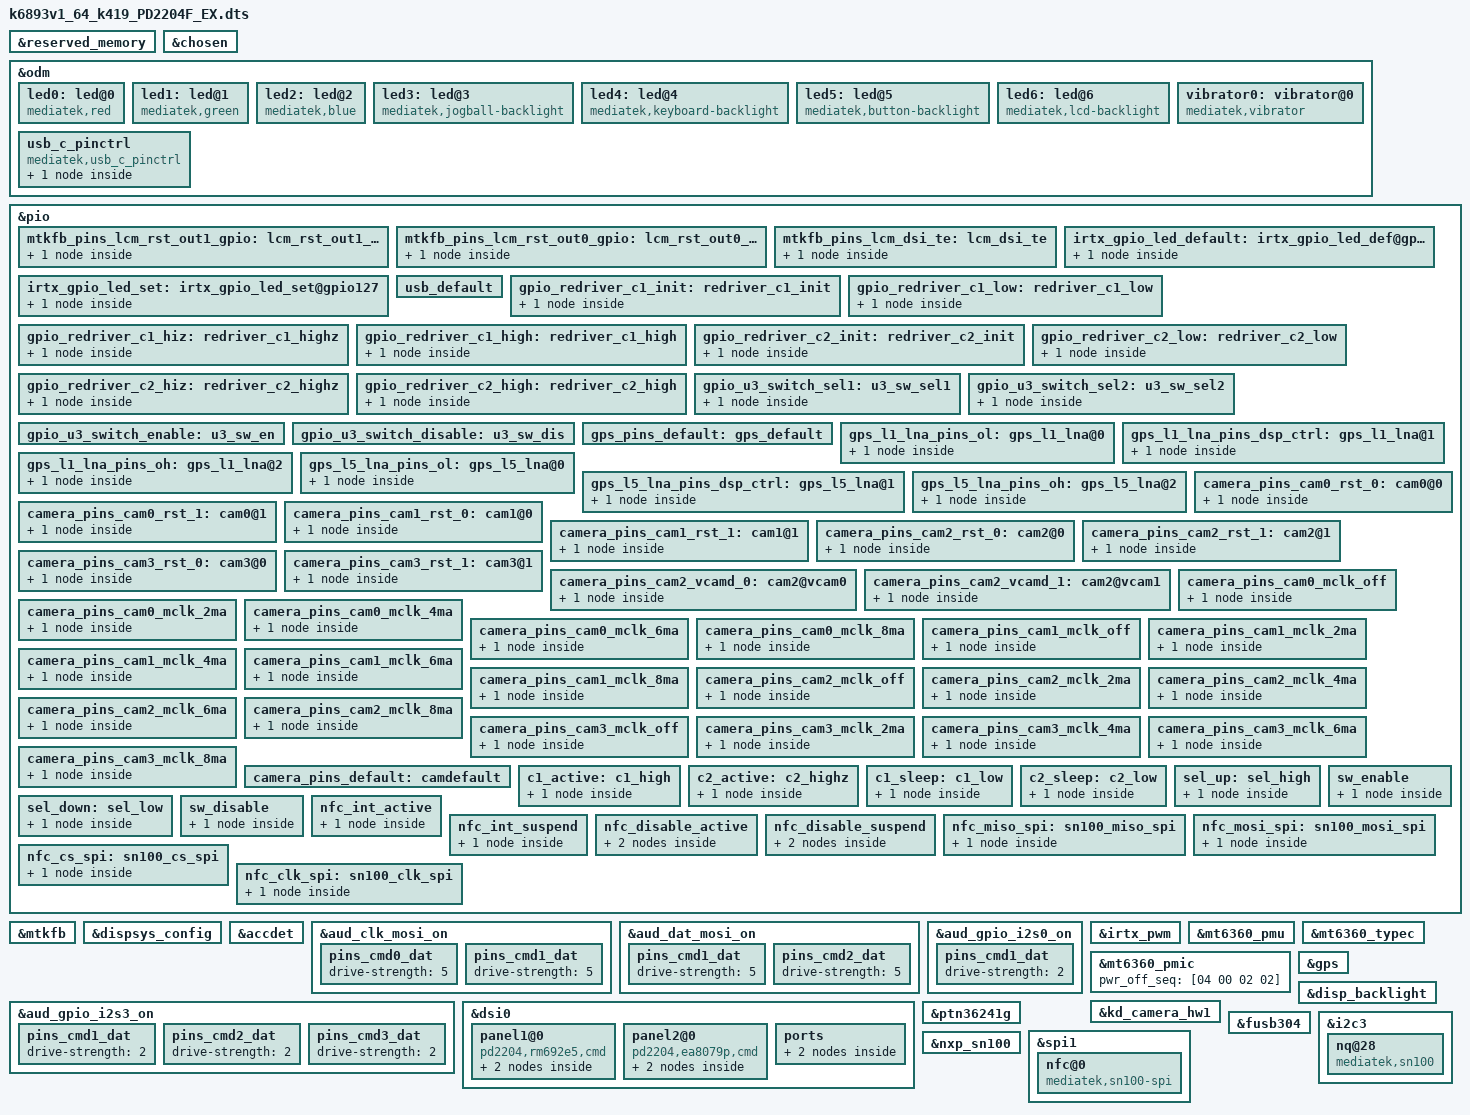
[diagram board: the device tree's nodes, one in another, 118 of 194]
// SPDX-License-Identifier: GPL-2.0
/*
 * Copyright (c) 2019 MediaTek Inc.
 *
 */
/dts-v1/;
/plugin/;
#include <dt-bindings/interrupt-controller/irq.h>
#include <dt-bindings/interrupt-controller/arm-gic.h>
#include <dt-bindings/spmi/spmi.h>
#include <dt-bindings/pinctrl/mt6885-pinfunc.h>
#include "mtk-vivo-tp-PD2204F_EX.dtsi"
#include "mediatek/fingerprint/mt6893-vivo-fp-PD2204F_EX.dtsi"
#include <generated/autoconf.h>

&reserved_memory {
};

/* chosen */
&chosen {

	atag,videolfb-fb_base_l = <0x7e020000>;
	atag,videolfb-fb_base_h = <0x0>;
	atag,videolfb-islcmfound = <1>;
	atag,videolfb-islcm_inited = <0>;
	atag,videolfb-fps= <6000>;
	atag,videolfb-vramSize= <0x1be0000>;
	atag,vivo-dsi-panel-type = "oled";
	atag,videolfb-project-name= "PD2204F_EX";
	atag,videolfb-lcmname=
		"nt35595_fhd_dsi_cmd_truly_nt50358_drv";
	default-backlight-level = <1146>;
};

&odm {
	led0:led@0 {
		compatible = "mediatek,red";
		led_mode = <0>;
		data = <1>;
		pwm_config = <0 0 0 0 0>;
	};
	led1:led@1 {
		compatible = "mediatek,green";
		led_mode = <0>;
		data = <1>;
		pwm_config = <0 0 0 0 0>;
	};
	led2:led@2 {
		compatible = "mediatek,blue";
		led_mode = <0>;
		data = <1>;
		pwm_config = <0 0 0 0 0>;
	};
	led3:led@3 {
		compatible = "mediatek,jogball-backlight";
		led_mode = <0>;
		data = <1>;
		pwm_config = <0 0 0 0 0>;
	};
	led4:led@4 {
		compatible = "mediatek,keyboard-backlight";
		led_mode = <0>;
		data = <1>;
		pwm_config = <0 0 0 0 0>;
	};
	led5:led@5 {
		compatible = "mediatek,button-backlight";
		led_mode = <0>;
		data = <1>;
		pwm_config = <0 0 0 0 0>;
	};
	led6:led@6 {
		compatible = "mediatek,lcd-backlight";
		led_mode = <4>;
		data = <1>;
		pwm_config = <0 1 0 0 0>;
	};
	vibrator0:vibrator@0 {
		compatible = "mediatek,vibrator";
		vib_timer = <25>;
		vib_limit = <9>;
		vib_vol= <9>;
	};
	usb_c_pinctrl:usb_c_pinctrl {
		compatible = "mediatek,usb_c_pinctrl";
	};
};

/* DISPSYS GPIO standardization */
&pio {

	mtkfb_pins_lcm_rst_out1_gpio: lcm_rst_out1_gpio {
		pins_cmd_dat {
			pinmux = <PINMUX_GPIO42__FUNC_GPIO42>;
			slew-rate = <1>;
			output-high;
		};
	};

	mtkfb_pins_lcm_rst_out0_gpio: lcm_rst_out0_gpio {
		pins_cmd_dat {
			pinmux = <PINMUX_GPIO42__FUNC_GPIO42>;
			slew-rate = <1>;
			output-low;
		};
	};

	mtkfb_pins_lcm_dsi_te: lcm_dsi_te {
		pins_cmd_dat {
			pinmux = <PINMUX_GPIO41__FUNC_DSI_TE>;
		};
	};
};

&mtkfb {
	pinctrl-names = "lcm_rst_out1_gpio", "lcm_rst_out0_gpio",
		"mode_te_te";
	pinctrl-4 = <&mtkfb_pins_lcm_rst_out1_gpio>;
	pinctrl-5 = <&mtkfb_pins_lcm_rst_out0_gpio>;
	pinctrl-6 = <&mtkfb_pins_lcm_dsi_te>;
	status = "okay";
};

&dispsys_config {
	pinctrl-names =
		"lcm_rst_out1_gpio", "lcm_rst_out0_gpio",
		"mode_te_te";
	pinctrl-0 = <&mtkfb_pins_lcm_rst_out1_gpio>;
	pinctrl-1 = <&mtkfb_pins_lcm_rst_out0_gpio>;
	pinctrl-2 = <&mtkfb_pins_lcm_dsi_te>;
	status = "okay";
};
/* DISPSYS GPIO standardization end */

/* accdet start */
&accdet {
	/* accdet micbias voltage: 0x09:2.85v 0x08:2.8v 0x07,
	 * 2.7v;0x05,2.5v;0x02,1.9v
	 */
	accdet-mic-vol = <7>;
	/* accdet pwm_width, pwm_thresh, fall_delay, rise_delay
	 * debounce0, debounce1, debounce3, debounce4
	 * eint pwm_width, eint pwm_thresh
	 * eint deb(debounce0, debounce1, debounce2, debounce3), inv_debounce
	 */
	headset-mode-setting = <0x500 0x500 1 0x1f0
				0x800 0x800 0x20 0x44
				0x4 0x1
				0x5 0x3 0x3 0x5 0xe>;
	accdet-plugout-debounce = <16>;
	/*1:ACC mode, 2:low cost without in bias, 6:low cost with in bias*/
	accdet-mic-mode = <2>;
	/*0--MD_MAX--UP_MAX--DW_MAX*/
	headset-three-key-threshold = <0 90 210 430>;
	headset-three-key-threshold-CDD = <0 121 192 600>;
	/*0--MD_MAX--VOICE_MAX--UP_MAX--DW_MAX*/
	headset-four-key-threshold = <0 60 106 210 430>;

	/* select VTH to 2v and 500k, use internal resitance */
	eint_use_ext_res = <0>;
	status = "okay";
};
/* accdet end */

/* Audio add for modify mosi & i2s driving */
/* 0:2mA 1:4mA 2:6mA 3:8mA 4:10mA 5:12mA 6:14mA 7:16mA */
&aud_clk_mosi_on {
	pins_cmd0_dat {
		drive-strength = <5>;
	};
	pins_cmd1_dat {
		drive-strength = <5>;
	};
};
&aud_dat_mosi_on {
	pins_cmd1_dat {
		drive-strength = <5>;
	};
	pins_cmd2_dat {
		drive-strength = <5>;
	};
};

&aud_gpio_i2s0_on {
	pins_cmd1_dat {
		drive-strength = <2>;
	};
};
&aud_gpio_i2s3_on {
	pins_cmd1_dat {
		drive-strength = <2>;
	};
	pins_cmd2_dat {
		drive-strength = <2>;
	};
	pins_cmd3_dat {
		drive-strength = <2>;
	};
};
/* Audio add End */

/* IRTX GPIO Start */
&irtx_pwm {
	pinctrl-names = "irtx_gpio_led_default", "irtx_gpio_led_set";
	pinctrl-0 = <&irtx_gpio_led_default>;
	pinctrl-1 = <&irtx_gpio_led_set>;
	status = "okay";
};
&pio {
	/* IRTX GPIO Settings -Start */
	/* default: GPIO0, output, high */
	irtx_gpio_led_default:irtx_gpio_led_def@gpio127 {
		pins_cmd_dat {
			pinmux = <PINMUX_GPIO127__FUNC_GPIO127>;
			slew-rate = <1>;
			bias-disable;
			output-low;
			input-schmitt-enable = <0>;
		};
	};

	irtx_gpio_led_set:irtx_gpio_led_set@gpio127 {
		pins_cmd_dat {
			pinmux = <PINMUX_GPIO127__FUNC_PWM_3>;
			slew-rate = <1>;
			output-high;
		};
	};
}; /* IRTX GPIO Settings -End */


&mt6360_pmu {
	mt6360,intr_gpio_num = <24>; // direct defined GPIO num //
	mt6360,intr_gpio = <&pio 24 0x0>;
};

&mt6360_pmic  {
	pwr_off_seq = [04 00 02 02];
};

&mt6360_typec {
	mt6360pd,intr_gpio_num = <25>; /* direct defined GPIO num */
	mt6360pd,intr_gpio = <&pio 25 0x0>;
};

/* USB SWITCH GPIO start */
&pio {
	usb_default: usb_default {
	};

	gpio_redriver_c1_init: redriver_c1_init {
		pins_cmd_dat {
			pinmux = <PINMUX_GPIO113__FUNC_GPIO113>;
			slew-rate = <1>;
			output-low;
		};
	};

	gpio_redriver_c1_low: redriver_c1_low {
		pins_cmd_dat {
			pinmux = <PINMUX_GPIO113__FUNC_GPIO113>;
			slew-rate = <1>;
			output-low;
		};
	};

	gpio_redriver_c1_hiz: redriver_c1_highz {
		pins_cmd_dat {
			pinmux = <PINMUX_GPIO113__FUNC_GPIO113>;
			slew-rate= <0>;
			bias-disable;
		};
	};

	gpio_redriver_c1_high: redriver_c1_high {
		pins_cmd_dat {
			pinmux = <PINMUX_GPIO113__FUNC_GPIO113>;
			slew-rate = <1>;
			output-high;
		};
	};

	gpio_redriver_c2_init: redriver_c2_init {
		pins_cmd_dat {
			pinmux = <PINMUX_GPIO112__FUNC_GPIO112>;
			slew-rate = <1>;
			output-low;
		};
	};

	gpio_redriver_c2_low: redriver_c2_low {
		pins_cmd_dat {
			pinmux = <PINMUX_GPIO112__FUNC_GPIO112>;
			slew-rate = <1>;
			output-low;
		};
	};

	gpio_redriver_c2_hiz: redriver_c2_highz {
		pins_cmd_dat {
			pinmux = <PINMUX_GPIO112__FUNC_GPIO112>;
			slew-rate= <0>;
			bias-disable;
		};
	};

	gpio_redriver_c2_high: redriver_c2_high {
		pins_cmd_dat {
			pinmux = <PINMUX_GPIO112__FUNC_GPIO112>;
			slew-rate = <1>;
			output-high;
		};
	};

	gpio_u3_switch_sel1: u3_sw_sel1 {
		pins_cmd_dat {
			pinmux = <PINMUX_GPIO111__FUNC_GPIO111>;
			slew-rate = <1>;
			output-low;
		};
	};

	gpio_u3_switch_sel2: u3_sw_sel2 {
		pins_cmd_dat {
			pinmux = <PINMUX_GPIO111__FUNC_GPIO111>;
			slew-rate = <1>;
			output-high;
		};
	};

	gpio_u3_switch_enable: u3_sw_en {
	};

	gpio_u3_switch_disable: u3_sw_dis {
	};
};

&usb_c_pinctrl {
	pinctrl-names = "usb_default",
		"redrv_c1_init",
		"redrv_c1_low",
		"redrv_c1_hiz",
		"redrv_c1_high",
		"redrv_c2_init",
		"redrv_c2_low",
		"redrv_c2_hiz",
		"redrv_c2_high",
		"switch_sel1",
		"switch_sel2",
		"switch_enable",
		"switch_disable";

	pinctrl-0 = <&usb_default>;
	pinctrl-1 = <&gpio_redriver_c1_init>;
	pinctrl-2 = <&gpio_redriver_c1_low>;
	pinctrl-3 = <&gpio_redriver_c1_hiz>;
	pinctrl-4 = <&gpio_redriver_c1_high>;
	pinctrl-5 = <&gpio_redriver_c2_init>;
	pinctrl-6 = <&gpio_redriver_c2_low>;
	pinctrl-7 = <&gpio_redriver_c2_hiz>;
	pinctrl-8 = <&gpio_redriver_c2_high>;
	pinctrl-9 = <&gpio_u3_switch_sel1>;
	pinctrl-10 = <&gpio_u3_switch_sel2>;
	pinctrl-11 = <&gpio_u3_switch_enable>;
	pinctrl-12 = <&gpio_u3_switch_disable>;
	status = "okay";

	usb_switch-data {
		en_pin_num = <0>;
		en_pin_val = <0>;
		sel_pin_num = <111>;
		sel_pin_val = <1>;
		c1_pin_num = <113>;
		c1_pin_val = <2>;
		c2_pin_num = <112>;
		c2_pin_val = <1>;
	};
};
/* USB SWITCH GPIO end */

/* GPS GPIO standardization start */
&pio {
	gps_pins_default: gps_default {
	};

	gps_l1_lna_pins_ol: gps_l1_lna@0 {
		pins_cmd_dat {
			pinmux = <PINMUX_GPIO162__FUNC_GPIO162>;
			output-low;
		};
	};
	gps_l1_lna_pins_dsp_ctrl: gps_l1_lna@1 {
		pins_cmd_dat {
			pinmux = <PINMUX_GPIO162__FUNC_GPS_L1_ELNA_EN>;
		};
	};
	gps_l1_lna_pins_oh: gps_l1_lna@2 {
		pins_cmd_dat {
			pinmux = <PINMUX_GPIO162__FUNC_GPIO162>;
			output-high;
		};
	};

	gps_l5_lna_pins_ol: gps_l5_lna@0 {
		pins_cmd_dat {
			pinmux = <PINMUX_GPIO163__FUNC_GPIO163>;
			output-low;
		};
	};
	gps_l5_lna_pins_dsp_ctrl: gps_l5_lna@1 {
		pins_cmd_dat {
			pinmux = <PINMUX_GPIO163__FUNC_GPS_L5_ELNA_EN>;
		};
	};
	gps_l5_lna_pins_oh: gps_l5_lna@2 {
		pins_cmd_dat {
			pinmux = <PINMUX_GPIO163__FUNC_GPIO163>;
			output-high;
		};
	};
};

&gps {
	pinctrl-names = "default",
		"gps_l1_lna_disable",
		"gps_l1_lna_dsp_ctrl",
		"gps_l1_lna_enable",
		"gps_l5_lna_disable",
		"gps_l5_lna_dsp_ctrl",
		"gps_l5_lna_enable";
	pinctrl-0 = <&gps_pins_default>;
	pinctrl-1 = <&gps_l1_lna_pins_ol>;
	pinctrl-2 = <&gps_l1_lna_pins_dsp_ctrl>;
	pinctrl-3 = <&gps_l1_lna_pins_oh>;
	pinctrl-4 = <&gps_l5_lna_pins_ol>;
	pinctrl-5 = <&gps_l5_lna_pins_dsp_ctrl>;
	pinctrl-6 = <&gps_l5_lna_pins_oh>;
	status = "okay";
};
/* GPS GPIO standardization end */

&dispsys_config {
	pinctrl-names =
	"lcm_rst_out1_gpio", "lcm_rst_out0_gpio",
		"mode_te_te";
	pinctrl-0 = <&mtkfb_pins_lcm_rst_out1_gpio>;
	pinctrl-1 = <&mtkfb_pins_lcm_rst_out0_gpio>;
	pinctrl-2 = <&mtkfb_pins_lcm_dsi_te>;

	helper-name = "MTK_DRM_OPT_STAGE",
		"MTK_DRM_OPT_USE_CMDQ",
		"MTK_DRM_OPT_USE_M4U",
		"MTK_DRM_OPT_SODI_SUPPORT",
		"MTK_DRM_OPT_IDLE_MGR",
		"MTK_DRM_OPT_IDLEMGR_SWTCH_DECOUPLE",
		"MTK_DRM_OPT_IDLEMGR_BY_REPAINT",
		"MTK_DRM_OPT_IDLEMGR_ENTER_ULPS",
		"MTK_DRM_OPT_IDLEMGR_KEEP_LP11",
		"MTK_DRM_OPT_DYNAMIC_RDMA_GOLDEN_SETTING",
		"MTK_DRM_OPT_IDLEMGR_DISABLE_ROUTINE_IRQ",
		"MTK_DRM_OPT_MET_LOG",
		"MTK_DRM_OPT_USE_PQ",
		"MTK_DRM_OPT_ESD_CHECK_RECOVERY",
		"MTK_DRM_OPT_ESD_CHECK_SWITCH",
		"MTK_DRM_OPT_PRESENT_FENCE",
		"MTK_DRM_OPT_RDMA_UNDERFLOW_AEE",
		"MTK_DRM_OPT_DSI_UNDERRUN_AEE",
		"MTK_DRM_OPT_HRT",
		"MTK_DRM_OPT_HRT_MODE",
		"MTK_DRM_OPT_DELAYED_TRIGGER",
		"MTK_DRM_OPT_OVL_EXT_LAYER",
		"MTK_DRM_OPT_AOD",
		"MTK_DRM_OPT_RPO",
		"MTK_DRM_OPT_DUAL_PIPE",
		"MTK_DRM_OPT_DC_BY_HRT",
		"MTK_DRM_OPT_OVL_WCG",
		"MTK_DRM_OPT_OVL_SBCH",
		"MTK_DRM_OPT_COMMIT_NO_WAIT_VBLANK",
		"MTK_DRM_OPT_MET",
		"MTK_DRM_OPT_REG_PARSER_RAW_DUMP",
		"MTK_DRM_OPT_VP_PQ",
		"MTK_DRM_OPT_GAME_PQ",
		"MTK_DRM_OPT_MMPATH",
		"MTK_DRM_OPT_HBM",
		"MTK_DRM_OPT_VDS_PATH_SWITCH",
		"MTK_DRM_OPT_LAYER_REC",
		"MTK_DRM_OPT_CLEAR_LAYER",
		"MTK_DRM_OPT_LFR",
		"MTK_DRM_OPT_SF_PF",
		"MTK_DRM_OPT_DYN_MIPI_CHANGE",
		"MTK_DRM_OPT_PRIM_DUAL_PIPE";

	helper-value = <0>, /*MTK_DRM_OPT_STAGE*/
		<1>, /*MTK_DRM_OPT_USE_CMDQ*/
		<1>, /*MTK_DRM_OPT_USE_M4U*/
		<0>, /*MTK_DRM_OPT_SODI_SUPPORT*/
		<1>, /*MTK_DRM_OPT_IDLE_MGR*/
		<0>, /*MTK_DRM_OPT_IDLEMGR_SWTCH_DECOUPLE*/
		<1>, /*MTK_DRM_OPT_IDLEMGR_BY_REPAINT*/
		<0>, /*MTK_DRM_OPT_IDLEMGR_ENTER_ULPS*/
		<0>, /*MTK_DRM_OPT_IDLEMGR_KEEP_LP11*/
		<0>, /*MTK_DRM_OPT_DYNAMIC_RDMA_GOLDEN_SETTING*/
		<1>, /*MTK_DRM_OPT_IDLEMGR_DISABLE_ROUTINE_IRQ*/
		<0>, /*MTK_DRM_OPT_MET_LOG*/
		<1>, /*MTK_DRM_OPT_USE_PQ*/
		<1>, /*MTK_DRM_OPT_ESD_CHECK_RECOVERY*/
		<1>, /*MTK_DRM_OPT_ESD_CHECK_SWITCH*/
		<1>, /*MTK_DRM_OPT_PRESENT_FENCE*/
		<0>, /*MTK_DRM_OPT_RDMA_UNDERFLOW_AEE*/
		<1>, /*MTK_DRM_OPT_DSI_UNDERRUN_AEE*/
		<1>, /*MTK_DRM_OPT_HRT*/
		<1>, /*MTK_DRM_OPT_HRT_MODE*/
		<0>, /*MTK_DRM_OPT_DELAYED_TRIGGER*/
		<1>, /*MTK_DRM_OPT_OVL_EXT_LAYER*/
		<1>, /*MTK_DRM_OPT_AOD*/
		<1>, /*MTK_DRM_OPT_RPO*/
		<0>, /*MTK_DRM_OPT_DUAL_PIPE*/
		<0>, /*MTK_DRM_OPT_DC_BY_HRT*/
		<1>, /*MTK_DRM_OPT_OVL_WCG*/
		<0>, /*MTK_DRM_OPT_OVL_SBCH*/
		<1>, /*MTK_DRM_OPT_COMMIT_NO_WAIT_VBLANK*/
		<0>, /*MTK_DRM_OPT_MET*/
		<0>, /*MTK_DRM_OPT_REG_PARSER_RAW_DUMP*/
		<0>, /*MTK_DRM_OPT_VP_PQ*/
		<0>, /*MTK_DRM_OPT_GAME_PQ*/
		<0>, /*MTK_DRM_OPT_MMPATH*/
		<1>, /*MTK_DRM_OPT_HBM*/
		<0>, /*MTK_DRM_OPT_VDS_PATH_SWITCH*/
		<0>, /*MTK_DRM_OPT_LAYER_REC*/
		<1>, /*MTK_DRM_OPT_CLEAR_LAYER*/
		<1>, /*MTK_DRM_OPT_LFR*/
		<1>, /*MTK_DRM_OPT_SF_PF*/
		<1>, /*MTK_DRM_OPT_DYN_MIPI_CHANGE*/
		<1>; /*MTK_DRM_OPT_PRIM_DUAL_PIPE*/

};

&disp_backlight {
	max-brightness = <4095>;
	led-bits = <12>;
	default-brightness = <573>;
	trans-bits = <12>;
	default-state = "on";
};

&dsi0 {
	status = "okay";
	#address-cells = <1>;
	#size-cells = <0>;
	panel1@0 {
		compatible = "pd2204,rm692e5,cmd";
		reg = <0>;
		vddi-supply = <&mt_pmic_vm18_ldo_reg>;
		vci-supply = <&mt_pmic_vfp_ldo_reg>;
		reset-gpios = <&pio 42 0>;
		vddr-gpios = <&pio 191 0>;
		err_flag-gpios = <&pio 7 0>;
		elvdd_ctrl-gpios = <&pio 55 0>;
		board-gpios = <&pio 52 0>;
		vddr_mos_ctrl-gpios = <&pio 13 0>;
		pinctrl-names = "default";
		port {
			panel_in1: endpoint {
				remote-endpoint = <&dsi_out>;
			};
		};
	};
	panel2@0 {
		compatible = "pd2204,ea8079p,cmd";
		reg = <1>;
		vddi-supply = <&mt_pmic_vm18_ldo_reg>;
		vci-supply = <&mt_pmic_vfp_ldo_reg>;
		reset-gpios = <&pio 42 0>;
		vddr-gpios = <&pio 191 0>;
		err_flag-gpios = <&pio 7 0>;
		elvdd_ctrl-gpios = <&pio 55 0>;
		board-gpios = <&pio 52 0>;
		vddr_mos_ctrl-gpios = <&pio 13 0>;
		pinctrl-names = "default";
		port {
			panel_in2: endpoint {
				remote-endpoint = <&dsi_out>;
			};
		};
	};
	ports {
		port {
			dsi_out: endpoint {
				remote-endpoint = <&panel_in1>;
			};
		};
	};
};

/* CAMERA GPIO standardization */
&pio {
	camera_pins_cam0_rst_0: cam0@0 {
		pins_cmd_dat {
			pinmux = <PINMUX_GPIO132__FUNC_GPIO132>;
			slew-rate = <1>;
			output-low;
		};
	};
	camera_pins_cam0_rst_1: cam0@1 {
		pins_cmd_dat {
			pinmux = <PINMUX_GPIO132__FUNC_GPIO132>;
			slew-rate = <1>;
			output-high;
		};
	};
	camera_pins_cam1_rst_0: cam1@0 {
		pins_cmd_dat {
			pinmux = <PINMUX_GPIO131__FUNC_GPIO131>;
			slew-rate = <1>;
			output-low;
		};
	};
	camera_pins_cam1_rst_1: cam1@1 {
		pins_cmd_dat {
			pinmux = <PINMUX_GPIO131__FUNC_GPIO131>;
			slew-rate = <1>;
			output-high;
		};
	};
	camera_pins_cam2_rst_0: cam2@0 {
		pins_cmd_dat {
			pinmux = <PINMUX_GPIO11__FUNC_GPIO11>;
			slew-rate = <1>;
			output-low;
		};
	};
	camera_pins_cam2_rst_1: cam2@1 {
		pins_cmd_dat {
			pinmux = <PINMUX_GPIO11__FUNC_GPIO11>;
			slew-rate = <1>;
			output-high;
		};
	};
	camera_pins_cam3_rst_0: cam3@0 {
		pins_cmd_dat {
			pinmux = <PINMUX_GPIO10__FUNC_GPIO10>;
			slew-rate = <1>;
			output-low;
		};
	};
	camera_pins_cam3_rst_1: cam3@1 {
		pins_cmd_dat {
			pinmux = <PINMUX_GPIO10__FUNC_GPIO10>;
			slew-rate = <1>;
			output-high;
		};
	};
/*main OIS power start
	camera_main_af_pins_vddois_low: camera_main_af_vddois_low {
		pins_cmd_dat {
			pinmux = <PINMUX_GPIO135__FUNC_GPIO135>;
			slew-rate = <1>;
			output-low;
		};
	};
	camera_main_af_pins_vddois_high: camera_main_af_vddois_high {
		pins_cmd_dat {
			pinmux = <PINMUX_GPIO135__FUNC_GPIO135>;
			slew-rate = <1>;
			output-high;
		};
	};
main OIS power end*/
/*main2 power start*/
	camera_pins_cam2_vcamd_0: cam2@vcam0 {
		pins_cmd_dat {
			pinmux = <PINMUX_GPIO135__FUNC_GPIO135>;
			slew-rate = <1>;
			output-low;
		};
	};
	camera_pins_cam2_vcamd_1: cam2@vcam1 {
		pins_cmd_dat {
			pinmux = <PINMUX_GPIO135__FUNC_GPIO135>;
			slew-rate = <1>;
			output-high;
		};
	};
/*main2 power end*/
/*main power start*/
/*main power end*/
/*sub power start*/
/*sub power end*/
/*main2 power start*/
/*main2 power end*/
/*mclk power start*/
	camera_pins_cam0_mclk_off: camera_pins_cam0_mclk_off {
		pins_cmd_dat {
			pinmux = <PINMUX_GPIO149__FUNC_GPIO149>;
			drive-strength = <0>;
		};
	};
	camera_pins_cam0_mclk_2ma: camera_pins_cam0_mclk_2ma {
		pins_cmd_dat {
			pinmux = <PINMUX_GPIO149__FUNC_CMMCLK0>;
			drive-strength = <0>;
		};
	};
	camera_pins_cam0_mclk_4ma: camera_pins_cam0_mclk_4ma {
		pins_cmd_dat {
			pinmux = <PINMUX_GPIO149__FUNC_CMMCLK0>;
			drive-strength = <1>;
		};
	};
	camera_pins_cam0_mclk_6ma: camera_pins_cam0_mclk_6ma {
		pins_cmd_dat {
			pinmux = <PINMUX_GPIO149__FUNC_CMMCLK0>;
			drive-strength = <2>;
		};
	};
	camera_pins_cam0_mclk_8ma: camera_pins_cam0_mclk_8ma {
		pins_cmd_dat {
			pinmux = <PINMUX_GPIO149__FUNC_CMMCLK0>;
			drive-strength = <3>;
		};
	};
	camera_pins_cam1_mclk_off: camera_pins_cam1_mclk_off {
		pins_cmd_dat {
			pinmux = <PINMUX_GPIO137__FUNC_GPIO137>;
			drive-strength = <0>;
		};
	};
	camera_pins_cam1_mclk_2ma: camera_pins_cam1_mclk_2ma {
		pins_cmd_dat {
			pinmux = <PINMUX_GPIO137__FUNC_CMMCLK4>;
			drive-strength = <0>;
		};
	};
	camera_pins_cam1_mclk_4ma: camera_pins_cam1_mclk_4ma {
		pins_cmd_dat {
			pinmux = <PINMUX_GPIO137__FUNC_CMMCLK4>;
			drive-strength = <1>;
		};
	};
	camera_pins_cam1_mclk_6ma: camera_pins_cam1_mclk_6ma {
		pins_cmd_dat {
			pinmux = <PINMUX_GPIO137__FUNC_CMMCLK4>;
			drive-strength = <2>;
		};
	};
	camera_pins_cam1_mclk_8ma: camera_pins_cam1_mclk_8ma {
		pins_cmd_dat {
			pinmux = <PINMUX_GPIO137__FUNC_CMMCLK4>;
			drive-strength = <3>;
		};
	};
	camera_pins_cam2_mclk_off: camera_pins_cam2_mclk_off {
		pins_cmd_dat {
			pinmux = <PINMUX_GPIO151__FUNC_GPIO151>;
			drive-strength = <0>;
		};
	};
	camera_pins_cam2_mclk_2ma: camera_pins_cam2_mclk_2ma {
		pins_cmd_dat {
			pinmux = <PINMUX_GPIO151__FUNC_CMMCLK2>;
			drive-strength = <0>;
		};
	};
	camera_pins_cam2_mclk_4ma: camera_pins_cam2_mclk_4ma {
		pins_cmd_dat {
			pinmux = <PINMUX_GPIO151__FUNC_CMMCLK2>;
			drive-strength = <1>;
		};
	};
	camera_pins_cam2_mclk_6ma: camera_pins_cam2_mclk_6ma {
		pins_cmd_dat {
			pinmux = <PINMUX_GPIO151__FUNC_CMMCLK2>;
			drive-strength = <2>;
		};
	};
	camera_pins_cam2_mclk_8ma: camera_pins_cam2_mclk_8ma {
		pins_cmd_dat {
			pinmux = <PINMUX_GPIO151__FUNC_CMMCLK2>;
			drive-strength = <3>;
		};
	};
	camera_pins_cam3_mclk_off: camera_pins_cam3_mclk_off {
		pins_cmd_dat {
			pinmux = <PINMUX_GPIO150__FUNC_GPIO150>;
			drive-strength = <0>;
		};
	};
	camera_pins_cam3_mclk_2ma: camera_pins_cam3_mclk_2ma {
		pins_cmd_dat {
			pinmux = <PINMUX_GPIO150__FUNC_CMMCLK1>;
			drive-strength = <0>;
		};
	};
	camera_pins_cam3_mclk_4ma: camera_pins_cam3_mclk_4ma {
		pins_cmd_dat {
			pinmux = <PINMUX_GPIO150__FUNC_CMMCLK1>;
			drive-strength = <1>;
		};
	};
	camera_pins_cam3_mclk_6ma: camera_pins_cam3_mclk_6ma {
		pins_cmd_dat {
			pinmux = <PINMUX_GPIO150__FUNC_CMMCLK1>;
			drive-strength = <2>;
		};
	};
	camera_pins_cam3_mclk_8ma: camera_pins_cam3_mclk_8ma {
		pins_cmd_dat {
			pinmux = <PINMUX_GPIO150__FUNC_CMMCLK1>;
			drive-strength = <3>;
		};
	};
	camera_pins_default: camdefault {
	};
	/*mclk end*/
};
/* CAMERA specify sensor */
&kd_camera_hw1 {
	pinctrl-names = "default",
			"cam0_rst0", "cam0_rst1",
			"cam1_rst0", "cam1_rst1",
			"cam2_rst0", "cam2_rst1",
			"cam3_rst0", "cam3_rst1",
			//"cam0_ldo_vddois_0", "cam0_ldo_vddois_1",
			"cam2_ldo_vcamd_0", "cam2_ldo_vcamd_1",
			"cam0_mclk_off",
			"cam0_mclk_2mA", "cam0_mclk_4mA",
			"cam0_mclk_6mA", "cam0_mclk_8mA",
			"cam1_mclk_off",
			"cam1_mclk_2mA", "cam1_mclk_4mA",
			"cam1_mclk_6mA", "cam1_mclk_8mA",
			"cam2_mclk_off",
			"cam2_mclk_2mA", "cam2_mclk_4mA",
			"cam2_mclk_6mA", "cam2_mclk_8mA",
			"cam3_mclk_off",
			"cam3_mclk_2mA", "cam3_mclk_4mA",
			"cam3_mclk_6mA", "cam3_mclk_8mA";

	pinctrl-0 = <&camera_pins_default>;
	pinctrl-1 = <&camera_pins_cam0_rst_0>;
	pinctrl-2 = <&camera_pins_cam0_rst_1>;
	pinctrl-3 = <&camera_pins_cam1_rst_0>;
	pinctrl-4 = <&camera_pins_cam1_rst_1>;
	pinctrl-5 = <&camera_pins_cam2_rst_0>;
	pinctrl-6 = <&camera_pins_cam2_rst_1>;
	pinctrl-7 = <&camera_pins_cam3_rst_0>;
	pinctrl-8 = <&camera_pins_cam3_rst_1>;
	pinctrl-9 = <&camera_pins_cam2_vcamd_0>;
	pinctrl-10 = <&camera_pins_cam2_vcamd_1>;
	pinctrl-11 = <&camera_pins_cam0_mclk_off>;
	pinctrl-12 = <&camera_pins_cam0_mclk_2ma>;
	pinctrl-13 = <&camera_pins_cam0_mclk_4ma>;
	pinctrl-14 = <&camera_pins_cam0_mclk_6ma>;
	pinctrl-15 = <&camera_pins_cam0_mclk_8ma>;
	pinctrl-16 = <&camera_pins_cam1_mclk_off>;
	pinctrl-17 = <&camera_pins_cam1_mclk_2ma>;
	pinctrl-18 = <&camera_pins_cam1_mclk_4ma>;
	pinctrl-19 = <&camera_pins_cam1_mclk_6ma>;
	pinctrl-20 = <&camera_pins_cam1_mclk_8ma>;
	pinctrl-21 = <&camera_pins_cam2_mclk_off>;
	pinctrl-22 = <&camera_pins_cam2_mclk_2ma>;
	pinctrl-23 = <&camera_pins_cam2_mclk_4ma>;
	pinctrl-24 = <&camera_pins_cam2_mclk_6ma>;
	pinctrl-25 = <&camera_pins_cam2_mclk_8ma>;
	pinctrl-26 = <&camera_pins_cam3_mclk_off>;
	pinctrl-27 = <&camera_pins_cam3_mclk_2ma>;
	pinctrl-28 = <&camera_pins_cam3_mclk_4ma>;
	pinctrl-29 = <&camera_pins_cam3_mclk_6ma>;
	pinctrl-30 = <&camera_pins_cam3_mclk_8ma>;
	status = "okay";
};
/* CAMERA specify sensor end */


/* usb typec mux */
&pio {
	c1_active: c1_high {
		pins_cmd_dat {
			pinmux = <PINMUX_GPIO113__FUNC_GPIO113>;
			output-high;
		};
	};

	c2_active: c2_highz {
		pins_cmd_dat {
			pinmux = <PINMUX_GPIO112__FUNC_GPIO112>;
			input-enable;
			bias-disable;
		};
	};

	c1_sleep: c1_low {
		pins_cmd_dat {
			pinmux = <PINMUX_GPIO113__FUNC_GPIO113>;
			output-low;
		};
	};

	c2_sleep: c2_low {
		pins_cmd_dat {
			pinmux = <PINMUX_GPIO112__FUNC_GPIO112>;
			output-low;
		};
	};

	sel_up: sel_high {
		pins_cmd_dat {
			pinmux = <PINMUX_GPIO111__FUNC_GPIO111>;
			output-high;
		};
	};

	sel_down: sel_low {
		pins_cmd_dat {
			pinmux = <PINMUX_GPIO111__FUNC_GPIO111>;
			output-low;
		};
	};

	sw_enable: sw_enable {
		pins_cmd_dat {
			pinmux = <PINMUX_GPIO110__FUNC_GPIO110>;
			output-low;
		};
	};

	sw_disable: sw_disable {
		pins_cmd_dat {
			pinmux = <PINMUX_GPIO110__FUNC_GPIO110>;
			output-low;
		};
	};
};

&ptn36241g {
	pinctrl-names = "c1_active", "c1_sleep",
		"c2_active", "c2_sleep";
	pinctrl-0 = <&c1_active>;
	pinctrl-1 = <&c1_sleep>;
	pinctrl-2 = <&c2_active>;
	pinctrl-3 = <&c2_sleep>;
	status = "okay";
};

&fusb304 {
	pinctrl-names = "sel_up", "sel_down",
		"enable", "disable";
	pinctrl-0 = <&sel_up>;
	pinctrl-1 = <&sel_down>;
	pinctrl-2 = <&sw_enable>;
	pinctrl-3 = <&sw_disable>;
	status = "okay";
};

/*nfc liuyang4 begin*/
/*NFC*/
&pio {
	nfc_int_active: nfc_int_active {
		pins_cmd0_dat {
			pinmux = <PINMUX_GPIO16__FUNC_GPIO16>;
			bias-pull-up;
		};
	};
	nfc_int_suspend: nfc_int_suspend {
		pins_cmd0_dat {
			pinmux = <PINMUX_GPIO16__FUNC_GPIO16>;
			bias-pull-up;
		};
	};
	nfc_disable_active: nfc_disable_active {
		pins_cmd0_dat {
			pinmux = <PINMUX_GPIO183__FUNC_GPIO183>;
			bias-pull-up;
		};
		pins_cmd1_dat {
			pinmux = <PINMUX_GPIO22__FUNC_GPIO22>;
			bias-pull-up;
		};
	};
	nfc_disable_suspend: nfc_disable_suspend {
		pins_cmd0_dat {
			pinmux = <PINMUX_GPIO183__FUNC_GPIO183>;
			bias-disable;
		};
		pins_cmd1_dat {
			pinmux = <PINMUX_GPIO22__FUNC_GPIO22>;
			bias-disable;
		};
	};

};
&i2c3 {
	status = "okay";
	#address-cells = <1>;
	#size-cells = <0>;
	clock-frequency = <400000>;
	mediatek,use-open-drain;
	nq@28 {
		compatible = "mediatek,sn100";
		reg = <0x28>;

		vivo,nfc_support = <1>;
		vivo,boardversion_shift = <5>;
		vivo,boardversion_mask = <1>;
		vivo,boardversion_num = <1>;
		vivo,boardversions = "1";

		mediatek,nq-irq = <&pio 16 0x00>;
		mediatek,nq-ven = <&pio 183 0x00>;
		mediatek,nq-firm = <&pio 22 0x00>;
		//mediatek,nq-clkreq = <&pio 17 0x00>;
		interrupt-parent = <&pio>;
		interrupts = <16 0>;
		interrupt-names = "nfc_irq";
		pinctrl-names = "nfc_active", "nfc_suspend";
		pinctrl-0 = <&nfc_int_active &nfc_disable_active>;
		pinctrl-1 = <&nfc_int_suspend &nfc_disable_suspend>;
	};
};
&spi1 {
	#address-cells = <1>;
	#size-cells = <0>;
	nfc@0 {
		compatible = "mediatek,sn100-spi";
		reg = <0>;
		spi-max-frequency = <10000000>;
		status = "okay";
	};
};

&nxp_sn100 {
    status = "okay";
	pinctrl-names = "miso_spi","mosi_spi","cs_spi","clk_spi";
	pinctrl-0 = <&nfc_miso_spi>;
	pinctrl-1 = <&nfc_mosi_spi>;
	pinctrl-2 = <&nfc_cs_spi>;
	pinctrl-3 = <&nfc_clk_spi>;

};

&pio {
	nfc_miso_spi: sn100_miso_spi {
		pins_cmd_dat {
			pinmux = <PINMUX_GPIO158__FUNC_SPI1_A_MI>;
			drive-strength = <4>;
		};
	};
	nfc_mosi_spi: sn100_mosi_spi {
		pins_cmd_dat {
			pinmux = <PINMUX_GPIO159__FUNC_SPI1_A_MO>;
			drive-strength = <4>;
		};
	};
	nfc_cs_spi: sn100_cs_spi {
		pins_cmd_dat {
			pinmux = <PINMUX_GPIO157__FUNC_SPI1_A_CSB>;
			drive-strength = <4>;
			//bias-pull-up;
		};
	};
	nfc_clk_spi: sn100_clk_spi {
		pins_cmd_dat {
			pinmux = <PINMUX_GPIO156__FUNC_SPI1_A_CLK>;
			drive-strength = <4>;
		};
	};
};
/*nfc liuyang4 end*/


//#include "mediatek/cust_mt6885_camera.dtsi"
#include "mediatek/vivo_lra/mtk6893-vivo-lra-PD2204-custom.dtsi"
#include "mediatek/cust_vivo_PD2204F_EX.dtsi"
/*#include <k6893v1_64_k419/cust.dtsi>*/
/*End of this file, DO NOT ADD ANYTHING HERE*/
